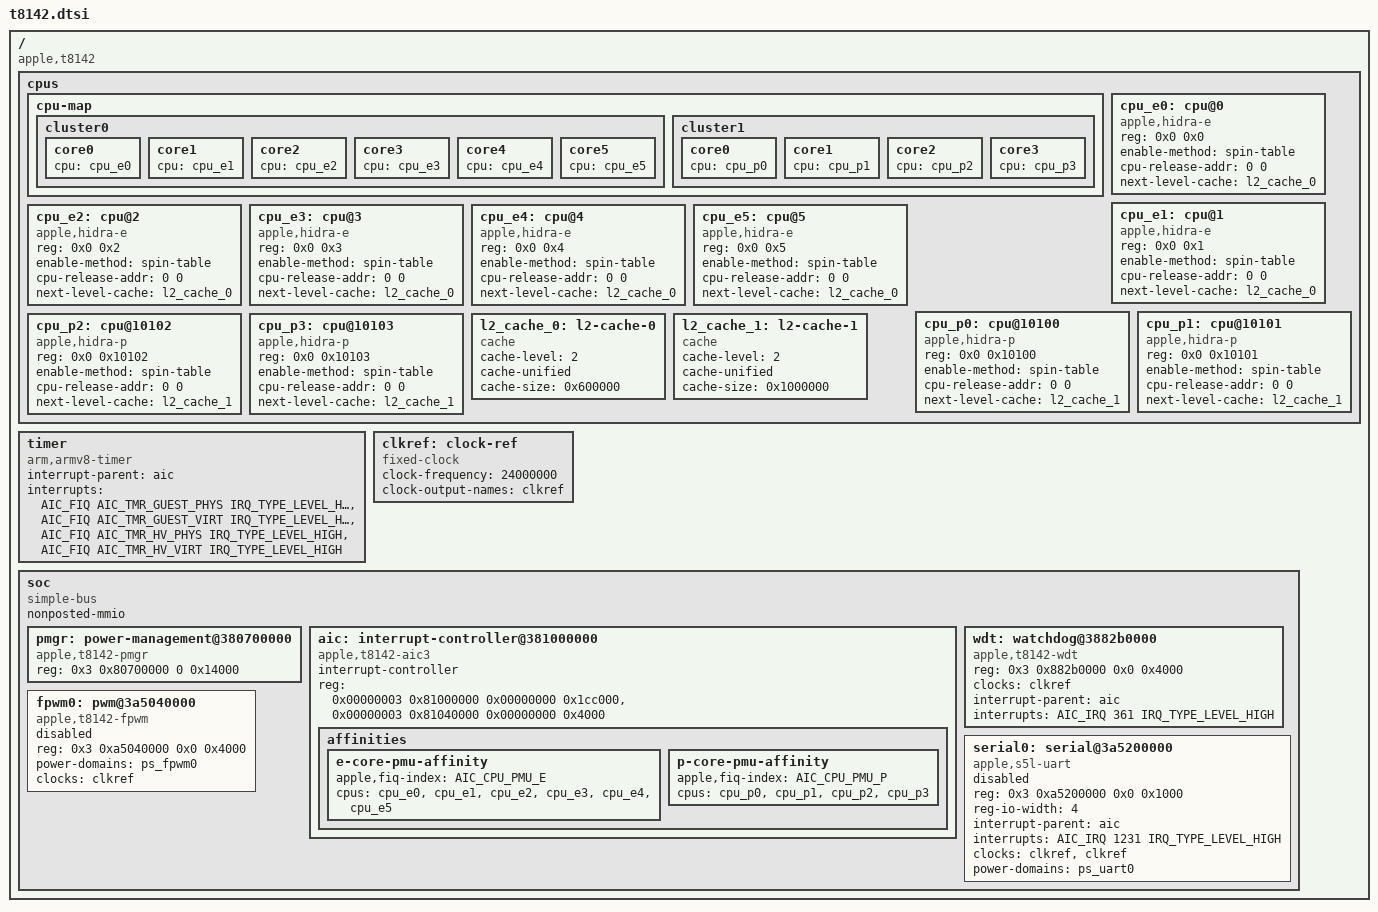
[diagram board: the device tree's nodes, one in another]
// SPDX-License-Identifier: GPL-2.0+ OR MIT
/*
 * Apple T8142 "M5" SoC
 *
 * Copyright The Asahi Linux Contributors
 */

#include <dt-bindings/interrupt-controller/apple-aic.h>
#include <dt-bindings/interrupt-controller/irq.h>

/ {
	compatible = "apple,t8142", "apple,arm-platform";

	#address-cells = <2>;
	#size-cells = <2>;

	cpus {
		#address-cells = <2>;
		#size-cells = <0>;

		cpu-map {
			cluster0 {
				core0 {
					cpu = <&cpu_e0>;
				};
				core1 {
					cpu = <&cpu_e1>;
				};
				core2 {
					cpu = <&cpu_e2>;
				};
				core3 {
					cpu = <&cpu_e3>;
				};
				core4 {
					cpu = <&cpu_e4>;
				};
				core5 {
					cpu = <&cpu_e5>;
				};
			};

			cluster1 {
				core0 {
					cpu = <&cpu_p0>;
				};
				core1 {
					cpu = <&cpu_p1>;
				};
				core2 {
					cpu = <&cpu_p2>;
				};
				core3 {
					cpu = <&cpu_p3>;
				};
			};
		};

		cpu_e0: cpu@0 {
			compatible = "apple,hidra-e";
			device_type = "cpu";
			reg = <0x0 0x0>;
			enable-method = "spin-table";
			cpu-release-addr = <0 0>;
			next-level-cache = <&l2_cache_0>;
		};

		cpu_e1: cpu@1 {
			compatible = "apple,hidra-e";
			device_type = "cpu";
			reg = <0x0 0x1>;
			enable-method = "spin-table";
			cpu-release-addr = <0 0>;
			next-level-cache = <&l2_cache_0>;
		};

		cpu_e2: cpu@2 {
			compatible = "apple,hidra-e";
			device_type = "cpu";
			reg = <0x0 0x2>;
			enable-method = "spin-table";
			cpu-release-addr = <0 0>;
			next-level-cache = <&l2_cache_0>;
		};

		cpu_e3: cpu@3 {
			compatible = "apple,hidra-e";
			device_type = "cpu";
			reg = <0x0 0x3>;
			enable-method = "spin-table";
			cpu-release-addr = <0 0>;
			next-level-cache = <&l2_cache_0>;
		};

		cpu_e4: cpu@4 {
			compatible = "apple,hidra-e";
			device_type = "cpu";
			reg = <0x0 0x4>;
			enable-method = "spin-table";
			cpu-release-addr = <0 0>;
			next-level-cache = <&l2_cache_0>;
		};

		cpu_e5: cpu@5 {
			compatible = "apple,hidra-e";
			device_type = "cpu";
			reg = <0x0 0x5>;
			enable-method = "spin-table";
			cpu-release-addr = <0 0>;
			next-level-cache = <&l2_cache_0>;
		};

		cpu_p0: cpu@10100 {
			compatible = "apple,hidra-p";
			device_type = "cpu";
			reg = <0x0 0x10100>;
			enable-method = "spin-table";
			cpu-release-addr = <0 0>;
			next-level-cache = <&l2_cache_1>;
		};

		cpu_p1: cpu@10101 {
			compatible = "apple,hidra-p";
			device_type = "cpu";
			reg = <0x0 0x10101>;
			enable-method = "spin-table";
			cpu-release-addr = <0 0>;
			next-level-cache = <&l2_cache_1>;
		};

		cpu_p2: cpu@10102 {
			compatible = "apple,hidra-p";
			device_type = "cpu";
			reg = <0x0 0x10102>;
			enable-method = "spin-table";
			cpu-release-addr = <0 0>;
			next-level-cache = <&l2_cache_1>;
		};

		cpu_p3: cpu@10103 {
			compatible = "apple,hidra-p";
			device_type = "cpu";
			reg = <0x0 0x10103>;
			enable-method = "spin-table";
			cpu-release-addr = <0 0>;
			next-level-cache = <&l2_cache_1>;
		};

		l2_cache_0: l2-cache-0 {
			compatible = "cache";
			cache-level = <2>;
			cache-unified;
			cache-size = <0x600000>;
		};

		l2_cache_1: l2-cache-1 {
			compatible = "cache";
			cache-level = <2>;
			cache-unified;
			cache-size = <0x1000000>;
		};
	};

	timer {
		compatible = "arm,armv8-timer";
		interrupt-parent = <&aic>;
		interrupt-names = "phys", "virt", "hyp-phys", "hyp-virt";
		interrupts = <AIC_FIQ AIC_TMR_GUEST_PHYS IRQ_TYPE_LEVEL_HIGH>,
			     <AIC_FIQ AIC_TMR_GUEST_VIRT IRQ_TYPE_LEVEL_HIGH>,
			     <AIC_FIQ AIC_TMR_HV_PHYS IRQ_TYPE_LEVEL_HIGH>,
			     <AIC_FIQ AIC_TMR_HV_VIRT IRQ_TYPE_LEVEL_HIGH>;
	};

	clkref: clock-ref {
		compatible = "fixed-clock";
		#clock-cells = <0>;
		clock-frequency = <24000000>;
		clock-output-names = "clkref";
	};

	soc: soc {
		compatible = "simple-bus";
		#address-cells = <2>;
		#size-cells = <2>;

		ranges;
		nonposted-mmio;

		pmgr: power-management@380700000 {
			compatible = "apple,t8142-pmgr", "apple,t8103-pmgr", "syscon", "simple-mfd";
			#address-cells = <1>;
			#size-cells = <1>;
			reg = <0x3 0x80700000 0 0x14000>;
			/* child nodes are added in t8142-pmgr.dtsi */
		};

		aic: interrupt-controller@381000000 {
			compatible = "apple,t8142-aic3", "apple,t8122-aic3";
			#interrupt-cells = <3>;
			interrupt-controller;
			reg = <0x00000003 0x81000000 0x00000000 0x1cc000>,
			      <0x00000003 0x81040000 0x00000000 0x4000>;
			reg-names = "core", "event";

			affinities {
				e-core-pmu-affinity {
					apple,fiq-index = <AIC_CPU_PMU_E>;
					cpus = <&cpu_e0 &cpu_e1 &cpu_e2 &cpu_e3 &cpu_e4 &cpu_e5>;
				};

				p-core-pmu-affinity {
					apple,fiq-index = <AIC_CPU_PMU_P>;
					cpus = <&cpu_p0 &cpu_p1 &cpu_p2 &cpu_p3>;
				};
			};
		};

		wdt: watchdog@3882b0000 {
			compatible = "apple,t8142-wdt", "apple,t8103-wdt";
			reg = <0x3 0x882b0000 0x0 0x4000>;
			clocks = <&clkref>;
			interrupt-parent = <&aic>;
			interrupts = <AIC_IRQ 361 IRQ_TYPE_LEVEL_HIGH>;
		};

		fpwm0: pwm@3a5040000 {
			compatible = "apple,t8142-fpwm", "apple,s5l-fpwm";
			reg = <0x3 0xa5040000 0x0 0x4000>;
			power-domains = <&ps_fpwm0>;
			clocks = <&clkref>;
			#pwm-cells = <2>;
			status = "disabled";
		};

		serial0: serial@3a5200000 {
			compatible = "apple,s5l-uart";
			reg = <0x3 0xa5200000 0x0 0x1000>;
			reg-io-width = <4>;
			interrupt-parent = <&aic>;
			interrupts = <AIC_IRQ 1231 IRQ_TYPE_LEVEL_HIGH>;
			clocks = <&clkref>, <&clkref>;
			clock-names = "uart", "clk_uart_baud0";
			power-domains = <&ps_uart0>;
			status = "disabled";
		};
	};
};

#include "t8142-pmgr.dtsi"
